# MSP430FR2522 register map
Vendor: msp430gen; File version: v0.4.0-28-gb0087ce-dirty
Registers are 16-bit, read-write, reset 0x0 unless marked. A register's access mark holds for its fields unless they carry their own. Offsets are from the block's base; lines under a group give offsets from that group; [hi:lo] are bit positions; {n}, {i} and the like mark numbered series; 'fields as' and 'values as' point back to an identical list; <NAME> marks a mode.

## Memory map
0x00000100 SFR
0x00000120 PMM
0x00000140 SYS
0x00000180 CS
0x000001A0 FRCTL
0x000001C0 CRC
0x000001CC WDT_A
0x00000200 P1
0x00000200 P2
0x00000300 RTC
0x00000380 TA0
0x000003C0 TA1
0x000004C0 MPY32
0x00000500 E_USCI_A0
0x00000540 E_USCI_B0
0x00000660 BAKMEM
0x00000700 ADC
0x00000B20 CAPTIVATE
0x00001A00 TLV size 0x100 — Device descriptors (TLV)
0x0000FF80 _INTERRUPTS

## Interrupts
49 CAPTIVATE (_INTERRUPTS) — 0xFFE2
50 PORT2 (_INTERRUPTS) — 0xFFE4
51 PORT1 (_INTERRUPTS) — 0xFFE6
52 ADC (_INTERRUPTS) — 0xFFE8
53 EUSCI_B0 (_INTERRUPTS) — 0xFFEA
54 EUSCI_A0 (_INTERRUPTS) — 0xFFEC
55 WDT (_INTERRUPTS) — 0xFFEE
56 RTC (_INTERRUPTS) — 0xFFF0
57 TIMER1_A1 (_INTERRUPTS) — 0xFFF2
58 TIMER1_A0 (_INTERRUPTS) — 0xFFF4
59 TIMER0_A1 (_INTERRUPTS) — 0xFFF6
60 TIMER0_A0 (_INTERRUPTS) — 0xFFF8
61 UNMI (_INTERRUPTS) — 0xFFFA
62 SYSNMI (_INTERRUPTS) — 0xFFFC

## P1
Base 0x00000200
0x00 P1IN 8-bit — Port 1 Input
0x02 P1OUT 8-bit — Port 1 Output
0x04 P1DIR 8-bit — Port 1 Direction
0x06 P1REN 8-bit — Port 1 Resistor Enable
0x0A P1SEL0 8-bit — Port 1 Select 0
0x0C P1SEL1 8-bit — Port 1 Select 1
0x0E P1IV — Port 1 Interrupt Vector Register
  [15:0] P1IV ro — Port 1 interrupt vector value
    0=NONE (No interrupt pending); 2=IFG0 (Interrupt Source: Port x.0 interrupt; Interrupt Flag: PxIFG.0; Interrupt Priority: Highest); 4=IFG1 (Interrupt Source: Port x.1 interrupt; Interrupt Flag: PxIFG.1); 6=IFG2 (Interrupt Source: Port x.2 interrupt; Interrupt Flag: PxIFG.2); 8=IFG3 (Interrupt Source: Port x.3 interrupt; Interrupt Flag: PxIFG.3); 10=IFG4 (Interrupt Source: Port x.4 interrupt; Interrupt Flag: PxIFG.4); 12=IFG5 (Interrupt Source: Port x.5 interrupt; Interrupt Flag: PxIFG.5); 14=IFG6 (Interrupt Source: Port x.6 interrupt; Interrupt Flag: PxIFG.6); 16=IFG7 (Interrupt Source: Port x.7 interrupt; Interrupt Flag: PxIFG.7; Interrupt Priority: Lowest)
0x16 P1SELC 8-bit — Port 1 Complement Select
0x18 P1IES 8-bit — Port 1 Interrupt Edge Select
0x1A P1IE 8-bit — Port 1 Interrupt Enable
0x1C P1IFG 8-bit — Port 1 Interrupt Flag

## P2
Base 0x00000200
0x01 P2IN 8-bit — Port 2 Input
0x03 P2OUT 8-bit — Port 2 Output
0x05 P2DIR 8-bit — Port 2 Direction
0x07 P2REN 8-bit — Port 2 Resistor Enable
0x0B P2SEL0 8-bit — Port 2 Select 0
0x0D P2SEL1 8-bit — Port 2 Select 1
0x17 P2SELC 8-bit — Port 2 Complement Select
0x19 P2IES 8-bit — Port 2 Interrupt Edge Select
0x1B P2IE 8-bit — Port 2 Interrupt Enable
0x1D P2IFG 8-bit — Port 2 Interrupt Flag
0x1E P2IV — Port 2 Interrupt Vector Register
  [15:0] P2IV ro — Port 2 interrupt vector value
    0=NONE (No interrupt pending); 2=IFG0 (Interrupt Source: Port x.0 interrupt; Interrupt Flag: PxIFG.0; Interrupt Priority: Highest); 4=IFG1 (Interrupt Source: Port x.1 interrupt; Interrupt Flag: PxIFG.1); 6=IFG2 (Interrupt Source: Port x.2 interrupt; Interrupt Flag: PxIFG.2); 8=IFG3 (Interrupt Source: Port x.3 interrupt; Interrupt Flag: PxIFG.3); 10=IFG4 (Interrupt Source: Port x.4 interrupt; Interrupt Flag: PxIFG.4); 12=IFG5 (Interrupt Source: Port x.5 interrupt; Interrupt Flag: PxIFG.5); 14=IFG6 (Interrupt Source: Port x.6 interrupt; Interrupt Flag: PxIFG.6); 16=IFG7 (Interrupt Source: Port x.7 interrupt; Interrupt Flag: PxIFG.7; Interrupt Priority: Lowest)

## SFR
Base 0x00000100
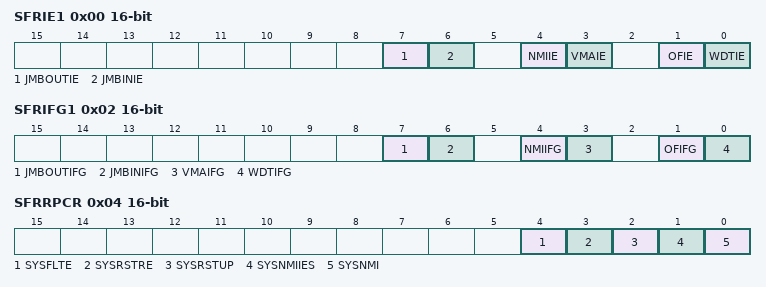
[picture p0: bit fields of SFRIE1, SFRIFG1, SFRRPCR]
0x00 SFRIE1 — Interrupt Enable
  [all] fields
    0=DISABLE (Interrupts disabled); 1=ENABLE (Interrupts enabled)
  [7] JMBOUTIE — JTAG mailbox output interrupt enable
  [6] JMBINIE — JTAG mailbox input interrupt enable
  [4] NMIIE — NMI pin interrupt enable
  [3] VMAIE — Vacant memory access interrupt enable
  [1] OFIE — Oscillator fault interrupt enable
  [0] WDTIE — Watchdog timer interrupt enable
0x02 SFRIFG1 — Interrupt Flag
  [7] JMBOUTIFG — JTAG mailbox output interrupt flag
    0=No interrupt pending. When in 16-bit mode (JMBMODE = 0), this bit is cleared automatically when JMBO0 has been written with a new message to the JTAG module by the CPU. When in 32-bit mode (JMBMODE = 1), this bit is cleared automatically when both JMBO0 and JMBO1 have been written with new messages to the JTAG module by the CPU. This bit is also cleared when the associated vector in SYSUNIV has been read.; 1=Interrupt pending. JMBO registers are ready for new messages. In 16-bit mode (JMBMODE = 0), JMBO0 has been received by the JTAG module and is ready for a new message from the CPU. In 32-bit mode (JMBMODE = 1), JMBO0 and JMBO1 have been received by the JTAG module and are ready for new messages from the CPU.
  [6] JMBINIFG — JTAG mailbox input interrupt flag
    0=No interrupt pending. When in 16-bit mode (JMBMODE = 0), this bit is cleared automatically when JMBI0 is read by the CPU. When in 32-bit mode (JMBMODE = 1), this bit is cleared automatically when both JMBI0 and JMBI1 have been read by the CPU. This bit is also cleared when the associated vector in SYSUNIV has been read; 1=Interrupt pending. A message is waiting in the JMBIN registers. In 16-bit mode (JMBMODE = 0) when JMBI0 has been written by the JTAG module. In 32-bit mode (JMBMODE = 1) when JMBI0 and JMBI1 have been written by the JTAG module.
  [4] NMIIFG — NMI pin interrupt flag
    0=No interrupt pending; 1=Interrupt pending
  [3] VMAIFG — Vacant memory access interrupt flag
    0=No interrupt pending; 1=Interrupt pending
  [1] OFIFG — Oscillator fault interrupt flag
    0=No interrupt pending; 1=Interrupt pending
  [0] WDTIFG — Watchdog timer interrupt flag
    0=No interrupt pending; 1=Interrupt pending
0x04 SFRRPCR — Reset Pin Control
  [4] SYSFLTE — Reset pin filter enable
    0=DISABLED (Reset pin filter disabled); 1=ENABLED (Reset pin filter enabled)
  [3] SYSRSTRE — Reset pin resistor enable
    0=DISABLE (Pullup or pulldown resistor at the RST/NMI pin is disabled); 1=ENABLE (Pullup or pulldown resistor at the RST/NMI pin is enabled)
  [2] SYSRSTUP — Reset resistor pin pullup or pulldown
    0=PULLDOWN (Pulldown is selected); 1=PULLUP (Pullup is selected)
  [1] SYSNMIIES — NMI edge select
    0=RISING (NMI on rising edge); 1=FALLING (NMI on falling edge)
  [0] SYSNMI — NMI select
    0=RESET (Reset function); 1=NMI (NMI function)
